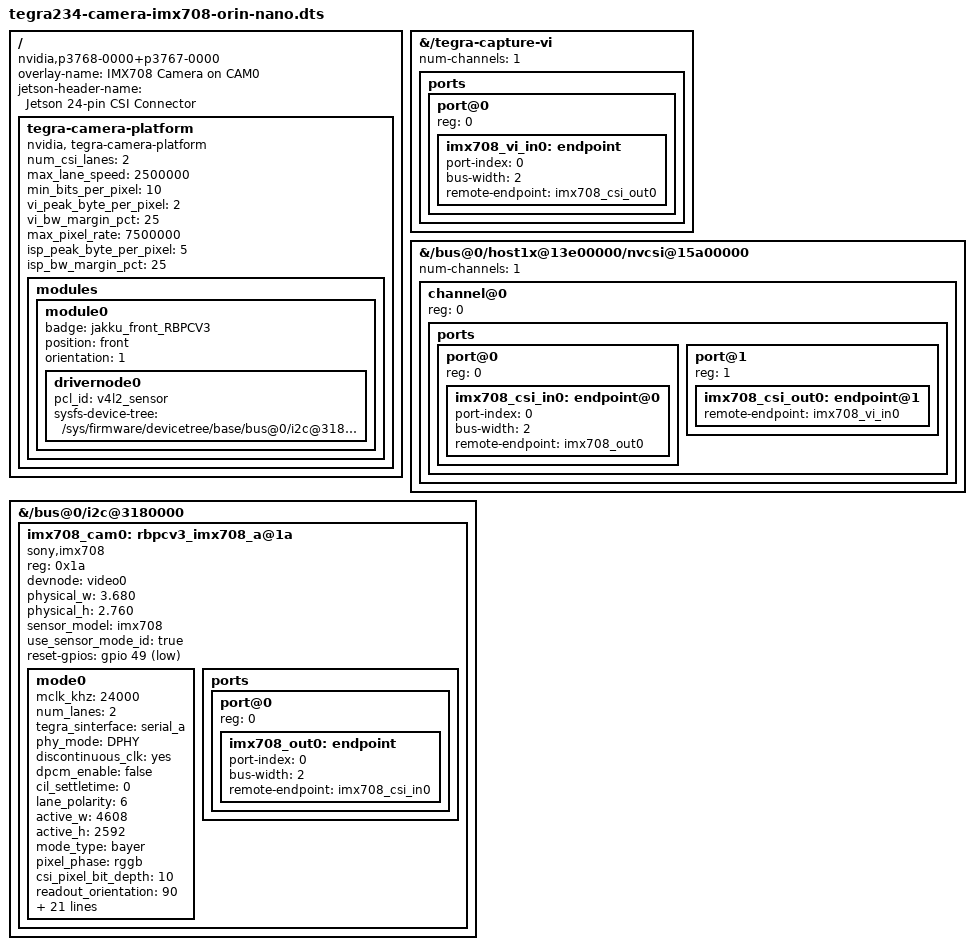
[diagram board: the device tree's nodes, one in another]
/*
 * Device Tree Overlay for IMX708 Camera on Jetson Orin Nano Developer Kit
 * JetPack 6.2 (L4T R36.4.x)
 *
 * Copyright (c) 2023-2024, RidgeRun <support@ridgerun.com>
 * Copyright (c) 2022-2024, NVIDIA CORPORATION. All rights reserved.
 *
 * Supports single camera on CAM0 (CSI port A)
 * I2C address: 0x1a on i2c@3180000 (bus 2)
 * Reset GPIO: PH.06 (CAM0_PWDN) - offset 49 in JetPack 6.2
 *
 * Note: JetPack 6.2 uses direct I2C without cam_i2cmux
 */

/dts-v1/;
/plugin/;

/ {
	overlay-name = "IMX708 Camera on CAM0";
	jetson-header-name = "Jetson 24-pin CSI Connector";
	compatible = "nvidia,p3768-0000+p3767-0000", "nvidia,p3768-0000+p3767-0003",
		     "nvidia,p3768-0000+p3767-0004", "nvidia,p3768-0000+p3767-0005",
		     "nvidia,p3767-0000", "nvidia,p3767-0003", "nvidia,p3767-0004",
		     "nvidia,p3767-0005", "nvidia,tegra234";

	/* Fragment 0: VI (Video Input) configuration */
	fragment@0 {
		target-path = "/tegra-capture-vi";
		__overlay__ {
			status = "okay";
			num-channels = <1>;
			ports {
				#address-cells = <1>;
				#size-cells = <0>;
				port@0 {
					reg = <0>;
					status = "okay";
					imx708_vi_in0: endpoint {
						status = "okay";
						port-index = <0>;
						bus-width = <2>;
						remote-endpoint = <&imx708_csi_out0>;
					};
				};
			};
		};
	};

	/* Fragment 1: NVCSI configuration */
	fragment@1 {
		target-path = "/bus@0/host1x@13e00000/nvcsi@15a00000";
		__overlay__ {
			status = "okay";
			num-channels = <1>;
			#address-cells = <1>;
			#size-cells = <0>;
			channel@0 {
				reg = <0>;
				status = "okay";
				ports {
					#address-cells = <1>;
					#size-cells = <0>;
					port@0 {
						reg = <0>;
						status = "okay";
						imx708_csi_in0: endpoint@0 {
							status = "okay";
							port-index = <0>;
							bus-width = <2>;
							remote-endpoint = <&imx708_out0>;
						};
					};
					port@1 {
						reg = <1>;
						status = "okay";
						imx708_csi_out0: endpoint@1 {
							status = "okay";
							remote-endpoint = <&imx708_vi_in0>;
						};
					};
				};
			};
		};
	};

	/* Fragment 2: I2C sensor node on i2c@3180000 (bus 2) */
	fragment@2 {
		target-path = "/bus@0/i2c@3180000";
		__overlay__ {
			status = "okay";
			#address-cells = <1>;
			#size-cells = <0>;

			imx708_cam0: rbpcv3_imx708_a@1a {
				compatible = "sony,imx708";
				reg = <0x1a>;
				status = "okay";

				devnode = "video0";
				physical_w = "3.680";
				physical_h = "2.760";
				sensor_model = "imx708";
				use_sensor_mode_id = "true";

				/* Reset GPIO - PH.06 (CAM0_PWDN) for CAM0 on Orin Nano */
				reset-gpios = <&gpio 49 1>; /* PH.06 = offset 49 in JetPack 6.2, GPIO_ACTIVE_LOW */

				/* IMX708_MODE_4608x2592_14fps */
				mode0 {
					mclk_khz = "24000";
					num_lanes = "2";
					tegra_sinterface = "serial_a";
					phy_mode = "DPHY";
					discontinuous_clk = "yes";
					dpcm_enable = "false";
					cil_settletime = "0";
					lane_polarity = "6";

					active_w = "4608";
					active_h = "2592";
					mode_type = "bayer";
					pixel_phase = "rggb";
					csi_pixel_bit_depth = "10";
					readout_orientation = "90";
					line_length = "4808";
					inherent_gain = "1";
					pix_clk_hz = "297600000";

					gain_factor = "16";
					framerate_factor = "1000000";
					exposure_factor = "1000000";
					min_gain_val = "16";
					max_gain_val = "256";
					step_gain_val = "1";
					default_gain = "16";
					min_hdr_ratio = "1";
					max_hdr_ratio = "1";
					min_framerate = "2000000";
					max_framerate = "14000000";
					step_framerate = "1";
					default_framerate = "14000000";
					min_exp_time = "500";
					max_exp_time = "65487";
					step_exp_time = "1";
					default_exp_time = "1600";
					embedded_metadata_height = "4";
				};

				ports {
					#address-cells = <1>;
					#size-cells = <0>;

					port@0 {
						reg = <0>;
						imx708_out0: endpoint {
							port-index = <0>;
							bus-width = <2>;
							remote-endpoint = <&imx708_csi_in0>;
						};
					};
				};
			};
		};
	};

	/* Fragment 3: tegra-camera-platform configuration */
	fragment@3 {
		target-path = "/";
		__overlay__ {
			tegra-camera-platform {
				compatible = "nvidia, tegra-camera-platform";
				num_csi_lanes = <2>;
				max_lane_speed = <2500000>;
				min_bits_per_pixel = <10>;
				vi_peak_byte_per_pixel = <2>;
				vi_bw_margin_pct = <25>;
				max_pixel_rate = <7500000>;
				isp_peak_byte_per_pixel = <5>;
				isp_bw_margin_pct = <25>;

				modules {
					module0 {
						status = "okay";
						badge = "jakku_front_RBPCV3";
						position = "front";
						orientation = "1";
						drivernode0 {
							pcl_id = "v4l2_sensor";
							sysfs-device-tree = "/sys/firmware/devicetree/base/bus@0/i2c@3180000/rbpcv3_imx708_a@1a";
						};
					};
				};
			};
		};
	};
};
